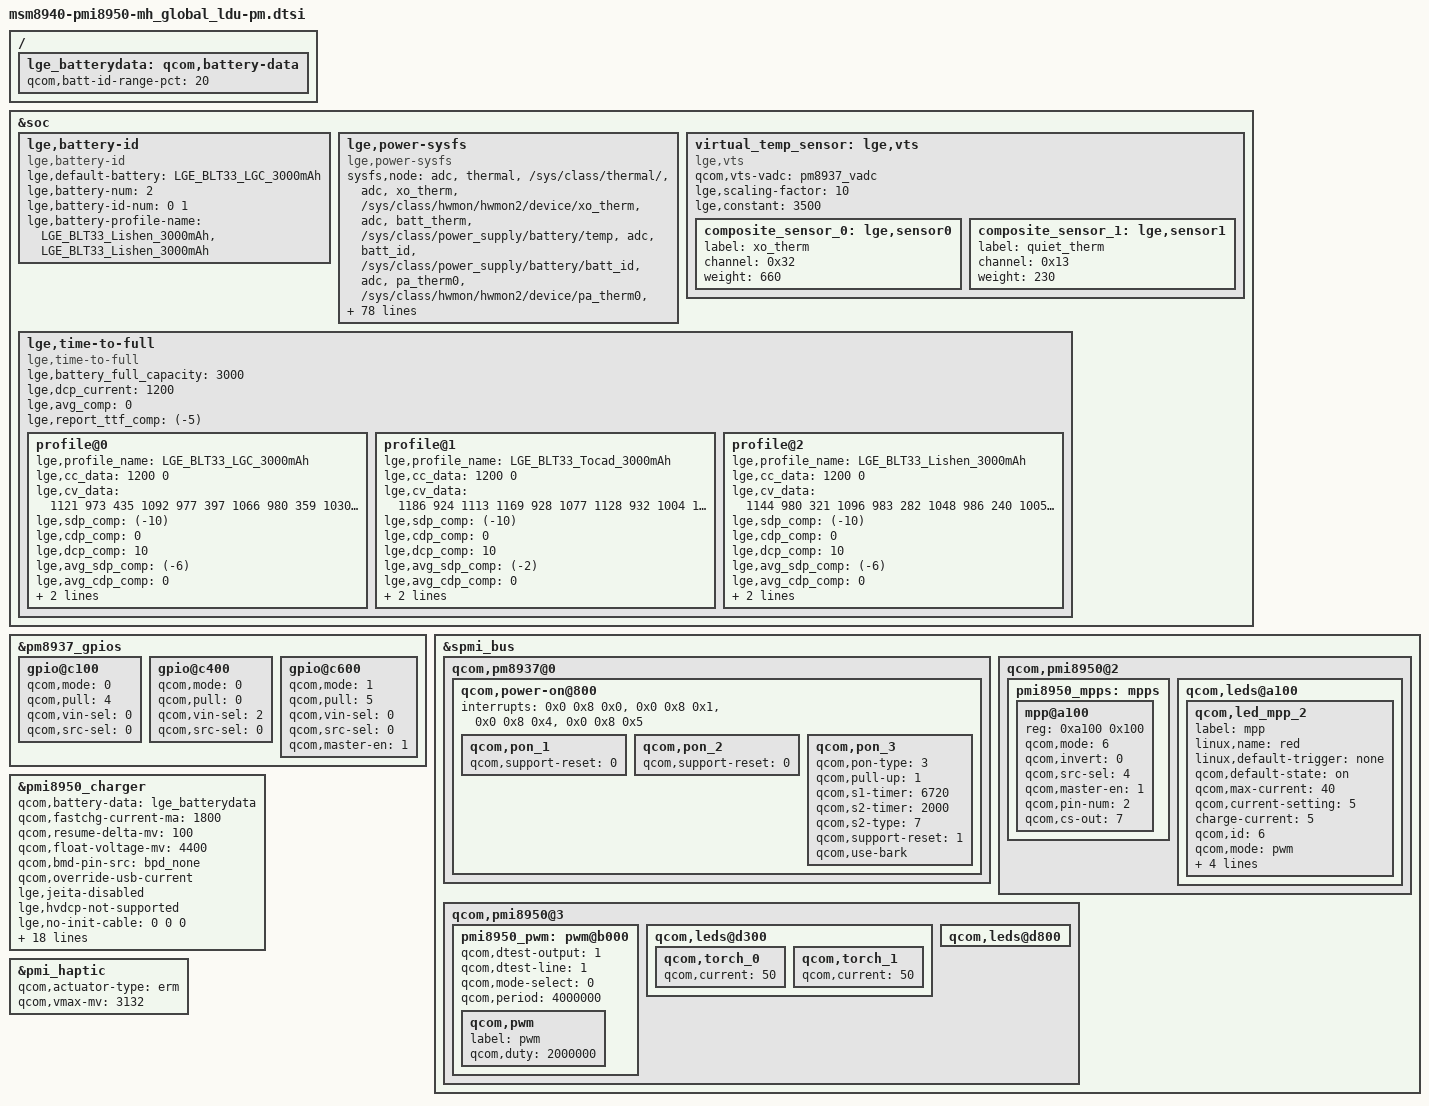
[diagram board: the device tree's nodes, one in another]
/*
 * Copyright (c) 2016, The Linux Foundation. All rights reserved.
 *
 * This program is free software; you can redistribute it and/or modify
 * it under the terms of the GNU General Public License version 2 and
 * only version 2 as published by the Free Software Foundation.
 *
 * This program is distributed in the hope that it will be useful,
 * but WITHOUT ANY WARRANTY; without even the implied warranty of
 * MERCHANTABILITY or FITNESS FOR A PARTICULAR PURPOSE.  See the
 * GNU General Public License for more details.
 */

/{
	lge_batterydata: qcom,battery-data {
		qcom,batt-id-range-pct = <20>;
		#include "../battery_profile/LGE_BLT33_LGC_3000mAh.dtsi"
		#include "../battery_profile/LGE_BLT33_Tocad_3000mAh.dtsi"
		#include "../battery_profile/LGE_BLT33_Lishen_3000mAh.dtsi"
	};
};

&soc {
	lge,battery-id{
		compatible = "lge,battery-id";
		/delete-property/ lge,restrict-mode-enabled;
		/*default battery profile*/
		lge,default-battery = "LGE_BLT33_LGC_3000mAh";
		/*Total number of combined of battery cell and battery id */
		lge,battery-num = <2>;
		/* battery id and battery profile match numbers */
		lge,battery-id-num = <0 1>;
		/* battery profile */
		lge,battery-profile-name = "LGE_BLT33_Lishen_3000mAh",
						"LGE_BLT33_Lishen_3000mAh";
	};

	lge,power-sysfs {
		compatible = "lge,power-sysfs";

		sysfs,node =
			/* group , user_node,  kernel node */
			/* ADC/MPP */
			"adc", "thermal", "/sys/class/thermal/",
			"adc", "xo_therm", "/sys/class/hwmon/hwmon2/device/xo_therm",
			"adc", "batt_therm", "/sys/class/power_supply/battery/temp",
			"adc", "batt_id", "/sys/class/power_supply/battery/batt_id",
			"adc", "pa_therm0", "/sys/class/hwmon/hwmon2/device/pa_therm0",
			"adc", "pa_therm1", "NULL", /* Not use */
			"adc", "usb_in", "/sys/class/hwmon/hwmon7/device/usbin",
			"adc", "vcoin", "/sys/class/hwmon/hwmon2/device/vcoin",
			"adc", "vph_pwr", "/sys/class/hwmon/hwmon2/device/vph_pwr",
			"adc", "usb_id", "/sys/class/hwmon/hwmon7/device/mpp1_usb_id",
			"adc", "quiet_therm", "/sys/class/hwmon/hwmon2/device/quiet_therm",
			/* Battery */
			"battery", "capacity", "/sys/class/power_supply/battery/capacity",
			"battery", "health", "/sys/class/power_supply/battery/health",
			"battery", "present", "/sys/class/power_supply/battery/present",
			"battery", "pseudo_batt", "/sys/class/power_supply/battery/pseudo_batt",
			"battery", "status", "/sys/class/power_supply/battery/status",
			"battery", "temp", "/sys/class/power_supply/battery/temp",
			"battery", "valid_batt_id", "/sys/class/power_supply/battery/valid_batt_id",
			"battery", "voltage_now", "/sys/class/power_supply/battery/voltage_now",
			/* Charger */
			"charger", "ac_online", "NULL",
			"charger", "usb_online", "/sys/class/power_supply/usb/online",
			"charger", "present", "/sys/class/power_supply/usb/present",
			"charger", "wlc_online", "NULL",
			"charger", "type", "/sys/class/power_supply/usb/type",
			"charger", "time_out", "/sys/class/power_supply/battery/safety_timer_enabled",
			"charger", "charging_enabled", "/sys/class/power_supply/battery/charging_enabled",
			"charger", "ibat_current", "/sys/class/power_supply/battery/current_now",
			"charger", "ichg_current", "/sys/class/power_supply/usb/current_max",
			"charger", "iusb_control", "NULL",
			"charger", "thermal_mitigation", "/sys/module/qpnp_linear_charger/parameters/qpnp_thermal_mitigation", /* Fix */
			"charger", "wlc_thermal_mitigation", "NULL",
			"charger", "usb_parallel_chg_status", "NULL",
			"charger", "usb_parallel_charging_enabled", "NULL",
			"charger", "quick_charging_state", "/sys/module/qpnp_smbcharger/parameters/charging_state",
			"charger", "chgstep", "/sys/class/power_supply/battery/device/chgstep",
			/* LCD Backlight */
			"lcd", "brightness", "/sys/class/leds/lcd-backlight/brightness",
			"lcd", "max_brightness", "/sys/class/leds/lcd-backlight/max_brightness",
			/* KEY LED */
			"key_led", "red_brightness", "/sys/class/leds/red/brightness", /* Fix */
			"key_led", "green_brightness", "/sys/class/leds/green/brightness", /* Fix */
			"key_led", "blue_brightness", "/sys/class/leds/blue/brightness", /* Fix */
			/* CPU */
			"cpu", "cpu_idle_modes", "NULL",
			/* GPU */
			"gpu", "busy", "/sys/class/kgsl/kgsl-3d0/gpubusy",
			/* PLATFORM */
			"platform", "speed_bin", "NULL",
			"platform", "pvs_bin", "NULL",
			"platform", "power_state", "/sys/power/autosleep",
			"platform", "poweron_alarm", "/sys/module/qpnp_rtc/parameters/poweron_alarm",
			"platform", "pcb_rev", "/sys/class/power_supply/battery/hw_rev",
			/* testmode */
			"testmode", "charge", "/sys/class/power_supply/battery/device/at_charge",
			"testmode", "chcomp", "/sys/class/power_supply/battery/device/at_chcomp",
			"testmode", "chgmodeoff", "/sys/class/power_supply/battery/charging_enabled",
			"testmode", "fuelrst", "NULL",
			"testmode", "rtc_time", "/dev/rtc0",
			"testmode", "pmrst", "NULL",
			"testmode", "battexit", "/sys/class/power_supply/battery/present"
			;
	};

	/* vts = (0.66*xo_therm) + (0.23*quiet_therm) + (3.5) */
	virtual_temp_sensor: lge,vts {
		compatible = "lge,vts";
		qcom,vts-vadc = <&pm8937_vadc>;
		lge,scaling-factor= <10>;
		lge,constant = <3500>;
		composite_sensor_0: lge,sensor0 {
			label = "xo_therm";
			channel = <0x32>;
			weight = <660>;
		};
		composite_sensor_1: lge,sensor1 {
			label = "quiet_therm";
			channel = <0x13>;
			weight = <230>;
		};
	};

	/* time to full */
	lge,time-to-full {
		compatible = "lge,time-to-full";
		lge,battery_full_capacity = <3000>;
		lge,dcp_current = <1200>;
		lge,avg_comp = <0>;
		lge,report_ttf_comp = <(-5)>;
		profile@0 {
			lge,profile_name = "LGE_BLT33_LGC_3000mAh";
				    /* current  soc */
			lge,cc_data = < 1200	0>;
				    /* current  soc    time */
			lge,cv_data = < 1121	973	435
					1092	977	397
					1066	980	359
					1030	983	316
					986	986	270
					941	989	222
					883	992	171
					831	995	117
					788	998	60
					739	1000	0>;
			lge,sdp_comp = <(-10)>;
			lge,cdp_comp = <0>;
			lge,dcp_comp = <10>;
			lge,avg_sdp_comp = <(-6)>;
			lge,avg_cdp_comp = <0>;
			lge,avg_dcp_comp = <0>;
			lge,min_comp = <2>;
		};
		profile@1 {
			lge,profile_name = "LGE_BLT33_Tocad_3000mAh";
				    /* current  soc */
			lge,cc_data = < 1200	0>;
				    /* current  soc    time */
			lge,cv_data = < 1186	924	1113
					1169	928	1077
					1128	932	1004
					1120	937	957
					1109	941	911
					1074	945	866
					1046	949	824
					1011	954	783
					976	958	739
					942	962	695
					914	966	649
					879	970	602
					844	973	552
					814	977	501
					783	980	447
					750	983	392
					716	986	334
					688	989	274
					657	992	210
					622	995	144
					590	998	74
					563	1000	0>;
			lge,sdp_comp = <(-10)>;
			lge,cdp_comp = <0>;
			lge,dcp_comp = <10>;
			lge,avg_sdp_comp = <(-2)>;
			lge,avg_cdp_comp = <0>;
			lge,avg_dcp_comp = <(-2)>;
			lge,min_comp = <2>;
		};
		profile@2 {
			lge,profile_name = "LGE_BLT33_Lishen_3000mAh";
				    /* current  soc */
			lge,cc_data = < 1200	0>;
				    /* current  soc    time */
			lge,cv_data = < 1144	980	321
					1096	983	282
					1048	986	240
					1005	989	197
					959	992	151
					911	995	103
					867	998	53
					820	1000	0>;
			lge,sdp_comp = <(-10)>;
			lge,cdp_comp = <0>;
			lge,dcp_comp = <10>;
			lge,avg_sdp_comp = <(-6)>;
			lge,avg_cdp_comp = <0>;
			lge,avg_dcp_comp = <0>;
			lge,min_comp = <2>;
		};
	};
};

&pm8937_gpios {
	gpio@c100 {
		qcom,mode = <0>;
		qcom,pull = <4>;
		qcom,vin-sel = <0>;
		qcom,src-sel = <0>;
		status = "okay";
	};
	gpio@c400 {
		qcom,mode = <0>;
		qcom,pull = <0>;
		qcom,vin-sel = <2>;
		qcom,src-sel = <0>;
		status = "okay";
	};
	gpio@c600 {
		status = "okay";
		qcom,mode = <1>;
		qcom,pull = <5>;
		qcom,vin-sel = <0>;
		qcom,src-sel = <0>;
		qcom,master-en = <1>;
	};
};

&spmi_bus {
	qcom,pm8937@0 {
		qcom,power-on@800 {
			interrupts = <0x0 0x8 0x0>,
				     <0x0 0x8 0x1>,
				     <0x0 0x8 0x4>,
				     <0x0 0x8 0x5>;
			interrupt-names = "kpdpwr", "resin",
				"resin-bark", "kpdpwr-resin-bark";

			qcom,pon_1 {
				status = "ok";
				qcom,support-reset = <0>;
			};
			qcom,pon_2 {
				status = "ok";
				qcom,support-reset = <0>;
			};
			qcom,pon_3 {
				status = "ok";
				qcom,pon-type = <3>;
				qcom,pull-up = <1>;
				qcom,s1-timer = <6720>;
				qcom,s2-timer = <2000>;
				qcom,s2-type = <7>;
				qcom,support-reset = <1>;
				qcom,use-bark;
			};
		};
	};

	qcom,pmi8950@2 {
		pmi8950_mpps: mpps {
			mpp@a100 {
				status = "okay";
				reg = <0xa100 0x100>;
				qcom,mode = <6>;
				qcom,invert = <0>;
				qcom,src-sel = <4>;
				qcom,master-en = <1>;
				qcom,pin-num = <2>;
				qcom,cs-out = <7>;
			};
		};
		qcom,leds@a100 {
			status = "okay";
			qcom,led_mpp_2 {
				label = "mpp";
				linux,name = "red";
				linux,default-trigger = "none";
				qcom,default-state = "on";
				qcom,max-current = <40>;
				qcom,current-setting = <5>;
				charge-current = <5>;
				qcom,id = <6>;
				qcom,mode = "pwm";
				qcom,pwm-us = <1000>;
				qcom,source-sel = <8>;
				qcom,mode-ctrl = <0x60>;
				pwms = <&pmi8950_pwm 0 0>;
			};
		};
	};

	qcom,pmi8950@3 {
		pmi8950_pwm: pwm@b000 {
			status = "ok";
			qcom,dtest-output = <1>;
			qcom,dtest-line = <1>;
			qcom,mode-select = <0>;
			qcom,period = <4000000>;
			qcom,pwm {
				label = "pwm";
				qcom,duty = <2000000>;
			};
		};
		qcom,leds@d300 {
			qcom,torch_0 {
				qcom,current = <50>;
			};
			qcom,torch_1 {
				qcom,current = <50>;
			};
		};
		qcom,leds@d800 {
			/delete-property/ qcom,en-ext-pfet-sc-pro;
		};
	};
};


&pmi8950_charger {
	qcom,battery-data = <&lge_batterydata>;
	qcom,fastchg-current-ma = <1800>;
	qcom,resume-delta-mv = <100>;
	qcom,float-voltage-mv = <4400>;
	qcom,bmd-pin-src = "bpd_thm";
	qcom,override-usb-current;
	lge,jeita-disabled;
	qcom,bmd-pin-src = "bpd_none";
	lge,hvdcp-not-supported;

	/* ref resistance 200K */
	lge,no-init-cable = <0 0 0>;
	lge,cable-mhl-1k = <5000 500 500>;
	lge,cable-u-28p7k = <10000 1800 500>;
	lge,cable-28p7k = <250000 1800 500>;
	lge,cable-56k = <600000 1500 1500>;
	lge,cable-100k = <620000 1800 500>;
	lge,cable-130k = <780000 1500 1500>;
	lge,cable-180k = <870000 1800 500>;
	lge,cable-200k = <910000 1800 500>;
	lge,cable-220k = <960000 1800 500>;
	lge,cable-270k = <1050000 1800 500>;
	lge,cable-330k = <1150000 1800 500>;
	lge,cable-620k = <1380000 1800 500>;
	lge,cable-910k = <1630000 1500 1500>;
	lge,cable-none = <1900000 1800  500>;

	lge,usb-max-current-ma = <1800>;
	lge,iusb = <1800 1000>;
	lge,ibat = <1800 1000>;
	lge,otp-ibat-limit = <900>;
};

&pmi_haptic {
        status = "okay";
        qcom,actuator-type = "erm";
        qcom,vmax-mv = <3132>;
};
